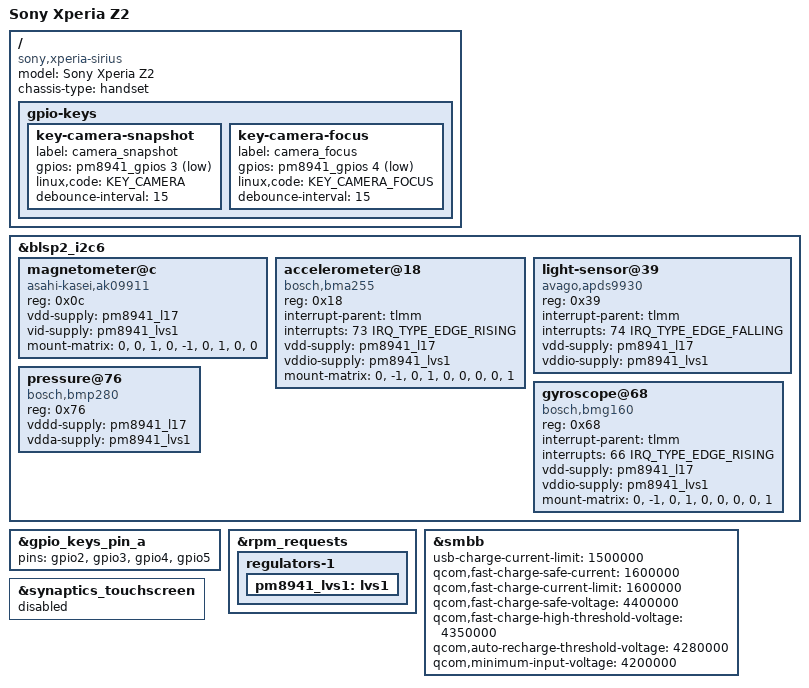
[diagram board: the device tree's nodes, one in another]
// SPDX-License-Identifier: GPL-2.0
/*
 * Sony Xperia Z2 (sirius), msm8974pro-AB.
 *
 * The fourth member of the shinano family, alongside aries, castor and leo,
 * which are already supported. Everything shared lives in the common dtsi;
 * this file carries only what differs.
 *
 * Charging values are Sony's, read out of the stock FOTA kernel's device tree
 * for this board (qcom,board-id = <0x08 0x00>, model "SoMC Sirius ROW"):
 * vddmax 4350 mV, vddsafe 4400 mV, vinmin 4200 mV, ibatmax and ibatsafe
 * 1600 mA, vbatdet-delta 70 mV, maxinput-usb 1500 mA.
 */

#include "qcom-msm8974pro-sony-xperia-shinano-common.dtsi"

/ {
	model = "Sony Xperia Z2";
	compatible = "sony,xperia-sirius", "qcom,msm8974pro", "qcom,msm8974";
	chassis-type = "handset";

	gpio-keys {
		key-camera-snapshot {
			label = "camera_snapshot";
			gpios = <&pm8941_gpios 3 GPIO_ACTIVE_LOW>;
			linux,code = <KEY_CAMERA>;
			debounce-interval = <15>;
		};

		key-camera-focus {
			label = "camera_focus";
			gpios = <&pm8941_gpios 4 GPIO_ACTIVE_LOW>;
			linux,code = <KEY_CAMERA_FOCUS>;
			debounce-interval = <15>;
		};
	};
};

&blsp2_i2c6 {
	status = "okay";

	magnetometer@c {
		compatible = "asahi-kasei,ak09911";
		reg = <0x0c>;

		vdd-supply = <&pm8941_l17>;
		vid-supply = <&pm8941_lvs1>;

		mount-matrix = "0", "0", "1",
			       "0", "-1", "0",
			       "1", "0", "0";
	};

	accelerometer@18 {
		compatible = "bosch,bma255";
		reg = <0x18>;

		interrupt-parent = <&tlmm>;
		interrupts = <73 IRQ_TYPE_EDGE_RISING>;

		vdd-supply = <&pm8941_l17>;
		vddio-supply = <&pm8941_lvs1>;

		mount-matrix = "0", "-1", "0",
			       "1", "0", "0",
			       "0", "0", "1";
	};

	light-sensor@39 {
		compatible = "avago,apds9930";
		reg = <0x39>;

		interrupt-parent = <&tlmm>;
		interrupts = <74 IRQ_TYPE_EDGE_FALLING>;

		vdd-supply = <&pm8941_l17>;
		vddio-supply = <&pm8941_lvs1>;
	};

	gyroscope@68 {
		compatible = "bosch,bmg160";
		reg = <0x68>;

		interrupt-parent = <&tlmm>;
		interrupts = <66 IRQ_TYPE_EDGE_RISING>;

		vdd-supply = <&pm8941_l17>;
		vddio-supply = <&pm8941_lvs1>;

		mount-matrix = "0", "-1", "0",
			       "1", "0", "0",
			       "0", "0", "1";
	};

	pressure@76 {
		compatible = "bosch,bmp280";
		reg = <0x76>;

		vddd-supply = <&pm8941_l17>;
		vdda-supply = <&pm8941_lvs1>;
	};
};

&gpio_keys_pin_a {
	pins = "gpio2", "gpio3", "gpio4", "gpio5";
};

&rpm_requests {
	regulators-1 {
		pm8941_lvs1: lvs1 {};
	};
};

&smbb {
	usb-charge-current-limit = <1500000>;
	qcom,fast-charge-safe-current = <1600000>;
	qcom,fast-charge-current-limit = <1600000>;
	qcom,fast-charge-safe-voltage = <4400000>;
	qcom,fast-charge-high-threshold-voltage = <4350000>;
	qcom,auto-recharge-threshold-voltage = <4280000>;
	qcom,minimum-input-voltage = <4200000>;

	status = "okay";
};

&synaptics_touchscreen {
	/*
	 * The Z2 uses a Maxim MAX1187x touch controller at 0x48 on this bus,
	 * not the Synaptics part the rest of the family has. No mainline
	 * driver exists for it yet, so the inherited node is turned off
	 * rather than left to bind against hardware that is not there.
	 */
	status = "disabled";
};
